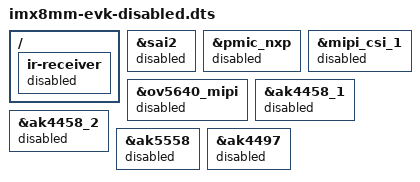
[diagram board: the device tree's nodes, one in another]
// $Id: 39322898fbf71de5a06c288ada52afc7d5558323 $

// #include "imx8mm-evk.dts" // must be included before

// Not currently in use
//&bt_sco_codec  {
//	status = "disabled";
//};
&sai2 {
	status = "disabled";
};

// Not installed
&pmic_nxp {
	status = "disabled";
};

/* MIPI-CSI camera not present currently */
&mipi_csi_1 {
	status = "disabled";
};

&ov5640_mipi {
	status = "disabled";
};

/* I2C Sound DAC  */
&ak4458_1 {
	status = "disabled";
};

&ak4458_2 {
	status = "disabled";
};

&ak5558 {
	status = "disabled";
};

&ak4497 {
	status = "disabled";
};

/ {
	ir-receiver {
		status = "disabled";
	};
};
